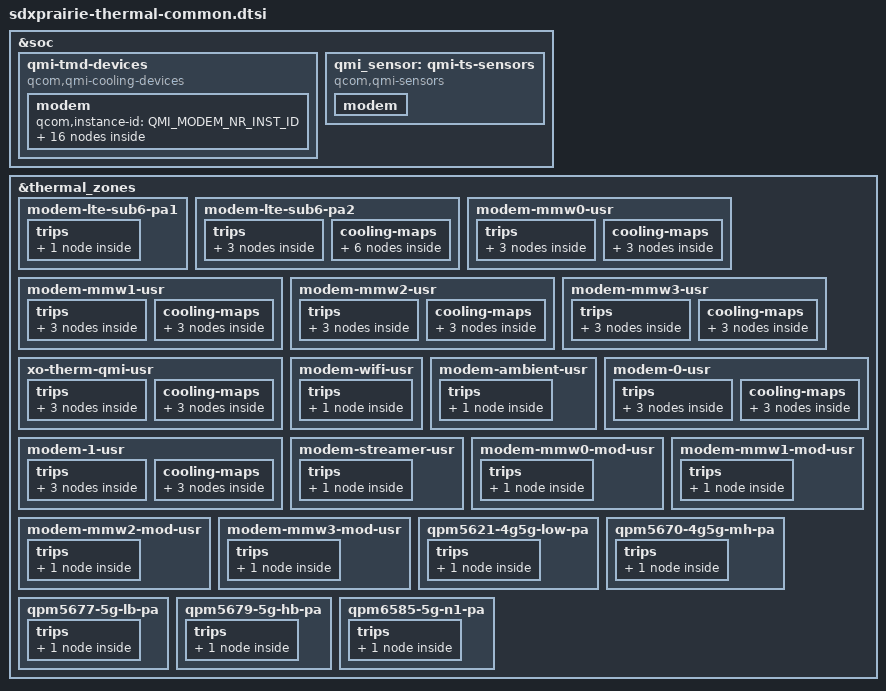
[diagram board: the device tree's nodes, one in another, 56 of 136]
/* Copyright (c) 2019, The Linux Foundation. All rights reserved.
 *
 * This program is free software; you can redistribute it and/or modify
 * it under the terms of the GNU General Public License version 2 and
 * only version 2 as published by the Free Software Foundation.
 *
 * This program is distributed in the hope that it will be useful,
 * but WITHOUT ANY WARRANTY; without even the implied warranty of
 * MERCHANTABILITY or FITNESS FOR A PARTICULAR PURPOSE.  See the
 * GNU General Public License for more details.
 */

#include <dt-bindings/thermal/qmi_thermal.h>

&soc {
	qmi-tmd-devices {
		compatible = "qcom,qmi-cooling-devices";

		modem {
			qcom,instance-id = <QMI_MODEM_NR_INST_ID>;

			modem_pa: modem_pa {
				qcom,qmi-dev-name = "pa";
				#cooling-cells = <2>;
			};

			modem_pa_fr1: modem_pa_fr1 {
				qcom,qmi-dev-name = "pa_fr1";
				#cooling-cells = <2>;
			};

			modem_tj: modem_tj {
				qcom,qmi-dev-name = "modem";
				#cooling-cells = <2>;
			};

			modem_current: modem_current {
				qcom,qmi-dev-name = "modem_current";
				#cooling-cells = <2>;
			};

			modem_skin: modem_skin {
				qcom,qmi-dev-name = "modem_skin";
				#cooling-cells = <2>;
			};

			modem_mmw_skin0: modem_mmw_skin0 {
				qcom,qmi-dev-name = "mmw_skin0";
				#cooling-cells = <2>;
			};

			modem_mmw_skin1: modem_mmw_skin1 {
				qcom,qmi-dev-name = "mmw_skin1";
				#cooling-cells = <2>;
			};

			modem_mmw_skin2: modem_mmw_skin2 {
				qcom,qmi-dev-name = "mmw_skin2";
				#cooling-cells = <2>;
			};

			modem_mmw_skin3: modem_mmw_skin3 {
				qcom,qmi-dev-name = "mmw_skin3";
				#cooling-cells = <2>;
			};

			modem_mmw0: modem_mmw0 {
				qcom,qmi-dev-name = "mmw0";
				#cooling-cells = <2>;
			};

			modem_mmw1: modem_mmw1 {
				qcom,qmi-dev-name = "mmw1";
				#cooling-cells = <2>;
			};

			modem_mmw2: modem_mmw2 {
				qcom,qmi-dev-name = "mmw2";
				#cooling-cells = <2>;
			};

			modem_mmw3: modem_mmw3 {
				qcom,qmi-dev-name = "mmw3";
				#cooling-cells = <2>;
			};

			modem_bcl: modem_bcl {
				qcom,qmi-dev-name = "vbatt_low";
				#cooling-cells = <2>;
			};

			modem_charge_state: modem_charge_state {
				qcom,qmi-dev-name = "charge_state";
				#cooling-cells = <2>;
			};

			modem_vdd: modem_vdd {
				qcom,qmi-dev-name = "cpuv_restriction_cold";
				#cooling-cells = <2>;
			};
		};
	};

	qmi_sensor: qmi-ts-sensors {
		compatible = "qcom,qmi-sensors";
		#thermal-sensor-cells = <1>;

		modem {
			qcom,instance-id = <QMI_MODEM_NR_INST_ID>;
			qcom,qmi-sensor-names = "pa",
						"pa_1",
						"qfe_wtr0",
						"modem_tsens",
						"qfe_mmw0",
						"qfe_mmw1",
						"qfe_mmw2",
						"qfe_mmw3",
						"xo_therm",
						"qfe_mmw_streamer0",
						"qfe_mmw0_mod",
						"qfe_mmw1_mod",
						"qfe_mmw2_mod",
						"qfe_mmw3_mod",
						"qfe_ret_pa0",
						"qfe_wtr_pa0",
						"qfe_wtr_pa1",
						"qfe_wtr_pa2",
						"qfe_wtr_pa3",
						"sys_therm1",
						"sys_therm2",
						"modem_tsens1";
		};
	};
};

&thermal_zones {
	modem-lte-sub6-pa1 {
		polling-delay-passive = <0>;
		polling-delay = <0>;
		thermal-governor = "user_space";
		thermal-sensors = <&qmi_sensor
				(QMI_MODEM_NR_INST_ID+QMI_QFE_WTR_0)>;
		wake-capable-sensor;
		trips {
			active-config0 {
				temperature = <125000>;
				hysteresis = <1000>;
				type = "passive";
			};
		};
	};

	modem-lte-sub6-pa2 {
		polling-delay-passive = <5000>;
		polling-delay = <1000>;
		thermal-governor = "step_wise";
		thermal-sensors = <&qmi_sensor
				(QMI_MODEM_NR_INST_ID+QMI_PA_1)>;
		wake-capable-sensor;
		trips {
			modemlte_trip0: modemlte-trip0 {
				temperature = <100000>;
				hysteresis = <15000>;
				type = "passive";
			};
			modemlte_trip1: modemlte-trip1 {
				temperature = <105000>;
				hysteresis = <15000>;
				type = "passive";
			};
			modemlte_trip2: modemlte-trip2 {
				temperature = <115000>;
				hysteresis = <30000>;
				type = "passive";
			};
		};
		cooling-maps {
			modemlte_lvl0 {
				trip = <&modemlte_trip0>;
				cooling-device = <&modem_pa 1 1>;
			};
			modemnr_lvl0 {
				trip = <&modemlte_trip0>;
				cooling-device = <&modem_pa_fr1 1 1>;
			};
			modemlte_lvl1 {
				trip = <&modemlte_trip1>;
				cooling-device = <&modem_pa 2 2>;
			};
			modemnr_lvl1 {
				trip = <&modemlte_trip1>;
				cooling-device = <&modem_pa_fr1 2 2>;
			};
			modemlte_lvl2 {
				trip = <&modemlte_trip2>;
				cooling-device = <&modem_pa 3 3>;
			};
			modemnr_lvl2 {
				trip = <&modemlte_trip2>;
				cooling-device = <&modem_pa_fr1 3 3>;
			};
		};
	};

	modem-mmw0-usr {
		polling-delay-passive = <0>;
		polling-delay = <0>;
		thermal-governor = "step_wise";
		thermal-sensors = <&qmi_sensor
				(QMI_MODEM_NR_INST_ID+QMI_QFE_MMW_0)>;
		wake-capable-sensor;
		trips {
			modemmmw0usr_trip0: modem-mmw0-usr-trip0 {
				temperature = <100000>;
				hysteresis = <15000>;
				type = "passive";
			};
			modemmmw0usr_trip1: modem-mmw0-usr-trip1 {
				temperature = <105000>;
				hysteresis = <15000>;
				type = "passive";
			};
			modemmmw0usr_trip2: modem-mmw0-usr-trip2 {
				temperature = <115000>;
				hysteresis = <30000>;
				type = "passive";
			};
		};
		cooling-maps {
			skin_modem0_lvl0 {
				trip = <&modemmmw0usr_trip0>;
				cooling-device = <&modem_mmw0 1 1>;
			};
			skin_modem0_lvl1 {
				trip = <&modemmmw0usr_trip1>;
				cooling-device = <&modem_mmw0 2 2>;
			};
			skin_modem0_lvl2 {
				trip = <&modemmmw0usr_trip2>;
				cooling-device = <&modem_mmw0 3 3>;
			};
		};
	};

	modem-mmw1-usr {
		polling-delay-passive = <0>;
		polling-delay = <0>;
		thermal-governor = "step_wise";
		thermal-sensors = <&qmi_sensor
				(QMI_MODEM_NR_INST_ID+QMI_QFE_MMW_1)>;
		wake-capable-sensor;
		trips {
			modemmmw1usr_trip0: modem-mmw1-usr-trip0 {
				temperature = <100000>;
				hysteresis = <15000>;
				type = "passive";
			};
			modemmmw1usr_trip1: modem-mmw1-usr-trip1 {
				temperature = <105000>;
				hysteresis = <15000>;
				type = "passive";
			};
			modemmmw1usr_trip2: modem-mmw1-usr-trip2 {
				temperature = <115000>;
				hysteresis = <30000>;
				type = "passive";
			};
		};
		cooling-maps {
			skin_modem0_lvl0 {
				trip = <&modemmmw1usr_trip0>;
				cooling-device = <&modem_mmw1 1 1>;
			};
			skin_modem0_lvl1 {
				trip = <&modemmmw1usr_trip1>;
				cooling-device = <&modem_mmw1 2 2>;
			};
			skin_modem0_lvl2 {
				trip = <&modemmmw1usr_trip2>;
				cooling-device = <&modem_mmw1 3 3>;
			};
		};
	};

	modem-mmw2-usr {
		polling-delay-passive = <0>;
		polling-delay = <0>;
		thermal-governor = "step_wise";
		thermal-sensors = <&qmi_sensor
				(QMI_MODEM_NR_INST_ID+QMI_QFE_MMW_2)>;
		wake-capable-sensor;
		trips {
			modemmmw2usr_trip0: modem-mmw2-usr-trip0 {
				temperature = <100000>;
				hysteresis = <15000>;
				type = "passive";
			};
			modemmmw2usr_trip1: modem-mmw2-usr-trip1 {
				temperature = <105000>;
				hysteresis = <15000>;
				type = "passive";
			};
			modemmmw2usr_trip2: modem-mmw2-usr-trip2 {
				temperature = <115000>;
				hysteresis = <30000>;
				type = "passive";
			};
		};
		cooling-maps {
			skin_modem0_lvl0 {
				trip = <&modemmmw2usr_trip0>;
				cooling-device = <&modem_mmw2 1 1>;
			};
			skin_modem0_lvl1 {
				trip = <&modemmmw2usr_trip1>;
				cooling-device = <&modem_mmw2 2 2>;
			};
			skin_modem0_lvl2 {
				trip = <&modemmmw2usr_trip2>;
				cooling-device = <&modem_mmw2 3 3>;
			};
		};
	};

	modem-mmw3-usr {
		polling-delay-passive = <0>;
		polling-delay = <0>;
		thermal-governor = "step_wise";
		thermal-sensors = <&qmi_sensor
				(QMI_MODEM_NR_INST_ID+QMI_QFE_MMW_3)>;
		wake-capable-sensor;
		trips {
			modemmmw3usr_trip0: modem-mmw3-usr-trip0 {
				temperature = <100000>;
				hysteresis = <15000>;
				type = "passive";
			};
			modemmmw3usr_trip1: modem-mmw3-usr-trip1 {
				temperature = <105000>;
				hysteresis = <15000>;
				type = "passive";
			};
			modemmmw3usr_trip2: modem-mmw3-usr-trip2 {
				temperature = <115000>;
				hysteresis = <30000>;
				type = "passive";
			};
		};
		cooling-maps {
			skin_modem0_lvl0 {
				trip = <&modemmmw3usr_trip0>;
				cooling-device = <&modem_mmw3 1 1>;
			};
			skin_modem0_lvl1 {
				trip = <&modemmmw3usr_trip1>;
				cooling-device = <&modem_mmw3 2 2>;
			};
			skin_modem0_lvl2 {
				trip = <&modemmmw3usr_trip2>;
				cooling-device = <&modem_mmw3 3 3>;
			};
		};
	};

	xo-therm-qmi-usr {
		polling-delay-passive = <0>;
		polling-delay = <0>;
		thermal-governor = "step_wise";
		thermal-sensors = <&qmi_sensor
				(QMI_MODEM_NR_INST_ID+QMI_XO_THERM)>;
		wake-capable-sensor;
		trips {
			xothermusr_trip0: xotherm-usr-trip0 {
				temperature = <100000>;
				hysteresis = <15000>;
				type = "passive";
			};
			xothermusr_trip1: xotherm-usr-trip1 {
				temperature = <105000>;
				hysteresis = <15000>;
				type = "passive";
			};
			xothermusr_trip2: xotherm-usr-trip2 {
				temperature = <115000>;
				hysteresis = <30000>;
				type = "passive";
			};
		};
		cooling-maps {
			xo_therm0_lvl0 {
				trip = <&xothermusr_trip0>;
				cooling-device = <&modem_skin 1 1>;
			};
			xo_therm0_lvl1 {
				trip = <&xothermusr_trip1>;
				cooling-device = <&modem_skin 2 2>;
			};
			xo_therm0_lvl2 {
				trip = <&xothermusr_trip2>;
				cooling-device = <&modem_skin 3 3>;
			};
		};
	};

	modem-wifi-usr {
		polling-delay-passive = <0>;
		polling-delay = <0>;
		thermal-governor = "user_space";
		thermal-sensors = <&qmi_sensor
				(QMI_MODEM_NR_INST_ID+QMI_SYS_THERM_1)>;
		wake-capable-sensor;
		trips {
			active-config0 {
				temperature = <125000>;
				hysteresis = <1000>;
				type = "passive";
			};
		};
	};

	modem-ambient-usr {
		polling-delay-passive = <0>;
		polling-delay = <0>;
		thermal-governor = "user_space";
		thermal-sensors = <&qmi_sensor
				(QMI_MODEM_NR_INST_ID+QMI_SYS_THERM_2)>;
		wake-capable-sensor;
		trips {
			active-config0 {
				temperature = <125000>;
				hysteresis = <1000>;
				type = "passive";
			};
		};
	};

	modem-0-usr {
		polling-delay-passive = <0>;
		polling-delay = <0>;
		thermal-governor = "step_wise";
		thermal-sensors = <&qmi_sensor
				(QMI_MODEM_NR_INST_ID+QMI_MODEM_TSENS)>;
		wake-capable-sensor;
		trips {
			modem0usr_trip0: modem0-usr-trip0 {
				temperature = <100000>;
				hysteresis = <15000>;
				type = "passive";
			};
			modem0usr_trip1: modem0-usr-trip1 {
				temperature = <105000>;
				hysteresis = <15000>;
				type = "passive";
			};
			modem0usr_trip2: modem0-usr-trip2 {
				temperature = <115000>;
				hysteresis = <30000>;
				type = "passive";
			};
		};
		cooling-maps {
			modem0_band_lvl0 {
				trip = <&modem0usr_trip0>;
				cooling-device = <&modem_tj 1 1>;
			};
			modem0_band_lvl1 {
				trip = <&modem0usr_trip1>;
				cooling-device = <&modem_tj 2 2>;
			};
			modem0_band_lvl2 {
				trip = <&modem0usr_trip2>;
				cooling-device = <&modem_tj 3 3>;
			};
		};
	};

	modem-1-usr {
		polling-delay-passive = <0>;
		polling-delay = <0>;
		thermal-governor = "step_wise";
		thermal-sensors = <&qmi_sensor
				(QMI_MODEM_NR_INST_ID+QMI_MODEM_TSENS_1)>;
		wake-capable-sensor;
		trips {
			modem1usr_trip0: modem1-usr-trip0 {
				temperature = <100000>;
				hysteresis = <15000>;
				type = "passive";
			};
			modem1usr_trip1: modem1-usr-trip1 {
				temperature = <105000>;
				hysteresis = <15000>;
				type = "passive";
			};
			modem1usr_trip2: modem1-usr-trip2 {
				temperature = <115000>;
				hysteresis = <30000>;
				type = "passive";
			};
		};
		cooling-maps {
			modem1_band_lvl0 {
				trip = <&modem1usr_trip0>;
				cooling-device = <&modem_tj 1 1>;
			};
			modem1_band_lvl1 {
				trip = <&modem1usr_trip1>;
				cooling-device = <&modem_tj 2 2>;
			};
			modem1_band_lvl2 {
				trip = <&modem1usr_trip2>;
				cooling-device = <&modem_tj 3 3>;
			};
		};
	};

	modem-streamer-usr {
		polling-delay-passive = <0>;
		polling-delay = <0>;
		thermal-governor = "user_space";
		thermal-sensors = <&qmi_sensor
				(QMI_MODEM_NR_INST_ID+QMI_QFE_MMW_STREAMER_0)>;
		wake-capable-sensor;
		trips {
			active-config0 {
				temperature = <125000>;
				hysteresis = <1000>;
				type = "passive";
			};
		};
	};

	modem-mmw0-mod-usr {
		polling-delay-passive = <0>;
		polling-delay = <0>;
		thermal-governor = "user_space";
		thermal-sensors = <&qmi_sensor
				(QMI_MODEM_NR_INST_ID+QMI_QFE_MMW_0_MOD)>;
		wake-capable-sensor;
		trips {
			active-config0 {
				temperature = <125000>;
				hysteresis = <1000>;
				type = "passive";
			};
		};
	};

	modem-mmw1-mod-usr {
		polling-delay-passive = <0>;
		polling-delay = <0>;
		thermal-governor = "user_space";
		thermal-sensors = <&qmi_sensor
				(QMI_MODEM_NR_INST_ID+QMI_QFE_MMW_1_MOD)>;
		wake-capable-sensor;
		trips {
			active-config0 {
				temperature = <125000>;
				hysteresis = <1000>;
				type = "passive";
			};
		};
	};

	modem-mmw2-mod-usr {
		polling-delay-passive = <0>;
		polling-delay = <0>;
		thermal-governor = "user_space";
		thermal-sensors = <&qmi_sensor
				(QMI_MODEM_NR_INST_ID+QMI_QFE_MMW_2_MOD)>;
		wake-capable-sensor;
		trips {
			active-config0 {
				temperature = <125000>;
				hysteresis = <1000>;
				type = "passive";
			};
		};
	};

	modem-mmw3-mod-usr {
		polling-delay-passive = <0>;
		polling-delay = <0>;
		thermal-governor = "user_space";
		thermal-sensors = <&qmi_sensor
				(QMI_MODEM_NR_INST_ID+QMI_QFE_MMW_3_MOD)>;
		wake-capable-sensor;
		trips {
			active-config0 {
				temperature = <125000>;
				hysteresis = <1000>;
				type = "passive";
			};
		};
	};

	qpm5621-4g5g-low-pa {
		polling-delay-passive = <0>;
		polling-delay = <0>;
		thermal-governor = "user_space";
		thermal-sensors = <&qmi_sensor
				(QMI_MODEM_NR_INST_ID+QMI_QFE_WTR_PA_0)>;
		wake-capable-sensor;
		trips {
			active-config0 {
				temperature = <125000>;
				hysteresis = <1000>;
				type = "passive";
			};
		};
	};

	qpm5670-4g5g-mh-pa {
		polling-delay-passive = <0>;
		polling-delay = <0>;
		thermal-governor = "user_space";
		thermal-sensors = <&qmi_sensor
				(QMI_MODEM_NR_INST_ID+QMI_QFE_WTR_PA_1)>;
		wake-capable-sensor;
		trips {
			active-config0 {
				temperature = <125000>;
				hysteresis = <1000>;
				type = "passive";
			};
		};
	};

	qpm5677-5g-lb-pa {
		polling-delay-passive = <0>;
		polling-delay = <0>;
		thermal-governor = "user_space";
		thermal-sensors = <&qmi_sensor
				(QMI_MODEM_NR_INST_ID+QMI_QFE_WTR_PA_2)>;
		wake-capable-sensor;
		trips {
			active-config0 {
				temperature = <125000>;
				hysteresis = <1000>;
				type = "passive";
			};
		};
	};

	qpm5679-5g-hb-pa {
		polling-delay-passive = <0>;
		polling-delay = <0>;
		thermal-governor = "user_space";
		thermal-sensors = <&qmi_sensor
				(QMI_MODEM_NR_INST_ID+QMI_QFE_RET_PA_0)>;
		wake-capable-sensor;
		trips {
			active-config0 {
				temperature = <125000>;
				hysteresis = <1000>;
				type = "passive";
			};
		};
	};

	qpm6585-5g-n1-pa {
		polling-delay-passive = <0>;
		polling-delay = <0>;
		thermal-governor = "user_space";
		thermal-sensors = <&qmi_sensor
				(QMI_MODEM_NR_INST_ID+QMI_QFE_WTR_PA_3)>;
		wake-capable-sensor;
		trips {
			active-config0 {
				temperature = <125000>;
				hysteresis = <1000>;
				type = "passive";
			};
		};
	};
};
